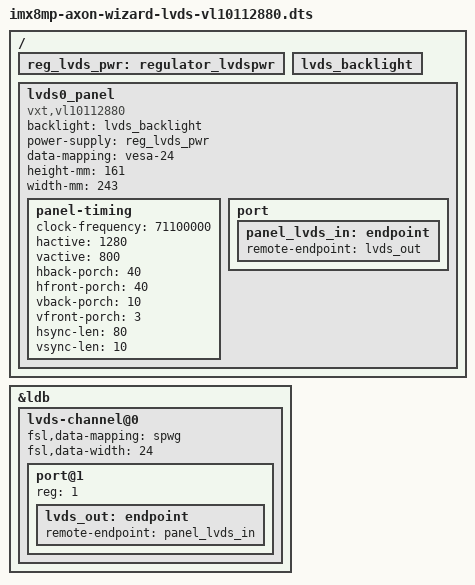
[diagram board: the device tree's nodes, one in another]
// SPDX-License-Identifier: (GPL-2.0+ OR MIT)
/*
 * Copyright 2020 Technexion Ltd.
 *
 * Author: Richard Hu <richard.hu@technexion.com>
 *
 */

#include "imx8mp-axon-wizard.dts"

/ {
	reg_lvds_pwr: regulator_lvdspwr {
		status = "okay";
	};

	lvds_backlight: lvds_backlight {
		status = "okay";
	};

	lvds0_panel {
		compatible = "vxt,vl10112880", "panel-lvds";
		backlight = <&lvds_backlight>;
		power-supply = <&reg_lvds_pwr>;

		data-mapping = "vesa-24";
		height-mm = <161>;
		width-mm = <243>;

		panel-timing {
			clock-frequency = <71100000>;
			hactive = <1280>;
			vactive = <800>;
			hback-porch = <40>;
			hfront-porch = <40>;
			vback-porch = <10>;
			vfront-porch = <3>;
			hsync-len = <80>;
			vsync-len = <10>;
		};

		port {
			panel_lvds_in: endpoint {
				remote-endpoint = <&lvds_out>;
			};
		};
	};
};

&ldb {
	status = "okay";

	lvds-channel@0 {
		fsl,data-mapping = "spwg";
		fsl,data-width = <24>;
		status = "okay";
		
		port@1 {
			reg = <1>;

			lvds_out: endpoint {
				remote-endpoint = <&panel_lvds_in>;
			};
		};
	};
};
